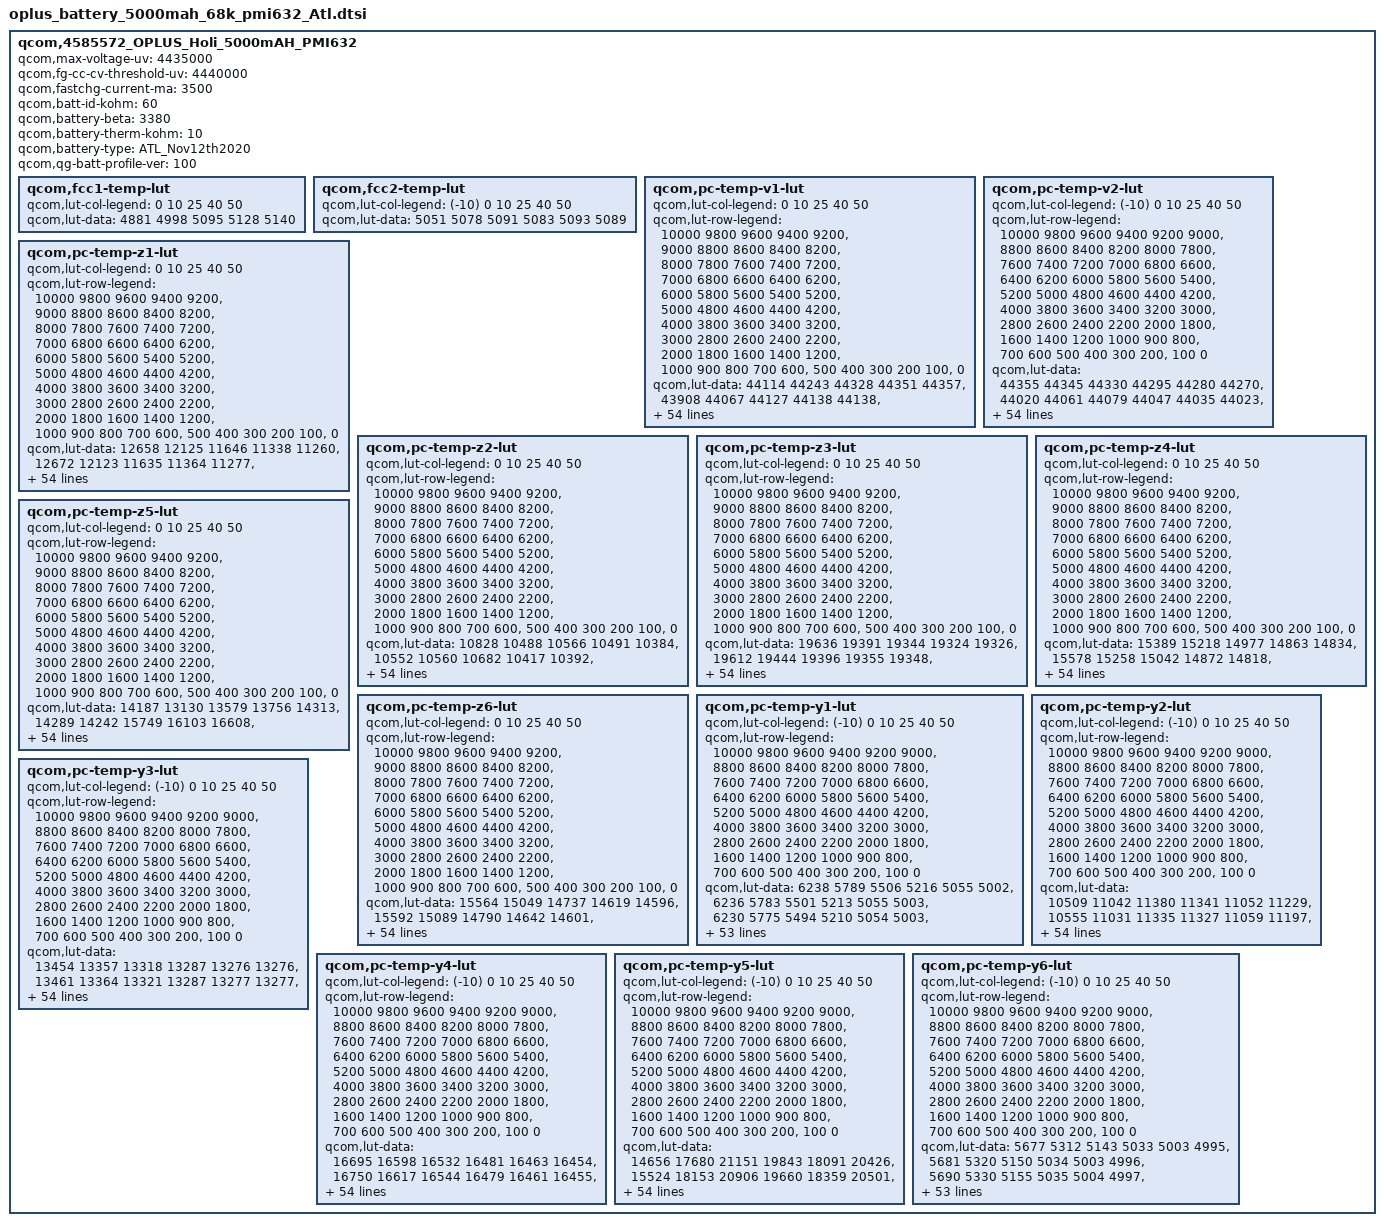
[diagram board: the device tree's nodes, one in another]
qcom,4585572_OPLUS_Holi_5000mAH_PMI632 {
    /* 4585572_OPLUS_Holi_5000mAH_PMI632_averaged_MasterSlave_Nov12th2020 */
    qcom,max-voltage-uv = <4435000>;
    qcom,fg-cc-cv-threshold-uv = <4440000>;
    qcom,fastchg-current-ma = <3500>;
    //qcom,batt-id-kohm = <68>;
    qcom,batt-id-kohm = <60>;
    qcom,battery-beta = <3380>;
    qcom,battery-therm-kohm = <10>;
    qcom,battery-type = "ATL_Nov12th2020";
    qcom,qg-batt-profile-ver = <100>;
    //qcom,jeita-soft-thresholds_oplus = <0x5E68 0x72A>;
    //qcom,jeita-hard-thresholds_oplus = <0x5E68 0x72A>;

	qcom,fcc1-temp-lut {
		qcom,lut-col-legend = <0 10 25 40 50>;
		qcom,lut-data = <4881 4998 5095 5128 5140>;
	};

	qcom,fcc2-temp-lut {
		qcom,lut-col-legend = <(-10) 0 10 25 40 50>;
		qcom,lut-data = <5051 5078 5091 5083 5093 5089>;
	};

	qcom,pc-temp-v1-lut {
		qcom,lut-col-legend = <0 10 25 40 50>;
		qcom,lut-row-legend = <10000 9800 9600 9400 9200>,
			<9000 8800 8600 8400 8200>,
			<8000 7800 7600 7400 7200>,
			<7000 6800 6600 6400 6200>,
			<6000 5800 5600 5400 5200>,
			<5000 4800 4600 4400 4200>,
			<4000 3800 3600 3400 3200>,
			<3000 2800 2600 2400 2200>,
			<2000 1800 1600 1400 1200>,
			<1000 900 800 700 600>,
			<500 400 300 200 100>,
			<0>;
		qcom,lut-data = <44114 44243 44328 44351 44357>,
			<43908 44067 44127 44138 44138>,
			<43693 43854 43932 43944 43944>,
			<43470 43639 43734 43747 43748>,
			<43242 43420 43523 43542 43544>,
			<43005 43193 43302 43328 43330>,
			<42764 42956 43072 43103 43107>,
			<42525 42712 42832 42868 42875>,
			<42287 42470 42588 42623 42635>,
			<42053 42228 42343 42380 42394>,
			<41824 41989 42099 42140 42151>,
			<41600 41756 41859 41901 41911>,
			<41381 41527 41624 41663 41677>,
			<41170 41306 41394 41428 41446>,
			<40962 41091 41169 41202 41221>,
			<40759 40881 40949 40982 40997>,
			<40560 40674 40739 40771 40781>,
			<40367 40472 40536 40567 40574>,
			<40180 40289 40342 40372 40376>,
			<39999 40130 40164 40187 40191>,
			<39827 39949 39991 40014 40021>,
			<39664 39682 39769 39809 39826>,
			<39480 39383 39461 39527 39552>,
			<39231 39172 39202 39262 39286>,
			<38990 39014 39053 39097 39119>,
			<38852 38890 38939 38972 38995>,
			<38760 38799 38830 38854 38875>,
			<38688 38723 38729 38744 38753>,
			<38628 38646 38636 38642 38640>,
			<38577 38569 38546 38541 38537>,
			<38524 38497 38463 38446 38442>,
			<38471 38426 38385 38361 38357>,
			<38419 38359 38311 38283 38282>,
			<38369 38300 38244 38212 38209>,
			<38321 38247 38188 38147 38137>,
			<38275 38199 38135 38086 38065>,
			<38236 38156 38083 38024 37994>,
			<38192 38114 38033 37964 37924>,
			<38121 38049 37968 37891 37842>,
			<38021 37948 37875 37793 37737>,
			<37909 37832 37765 37678 37617>,
			<37781 37708 37645 37558 37492>,
			<37633 37567 37507 37426 37357>,
			<37453 37394 37342 37263 37192>,
			<37292 37236 37189 37122 37052>,
			<37214 37138 37086 37034 36975>,
			<37173 37107 37063 37006 36950>,
			<37154 37088 37042 36990 36931>,
			<37122 37062 37023 36968 36907>,
			<37067 37017 36968 36901 36829>,
			<36846 36784 36716 36619 36528>,
			<36387 36333 36270 36168 36074>,
			<35786 35735 35676 35578 35483>,
			<34956 34909 34860 34764 34666>,
			<33578 33568 33574 33487 33385>,
			<30000 30000 30000 30000 30000>;
	};

	qcom,pc-temp-v2-lut {
		qcom,lut-col-legend = <(-10) 0 10 25 40 50>;
		qcom,lut-row-legend = <10000 9800 9600 9400 9200 9000>,
			<8800 8600 8400 8200 8000 7800>,
			<7600 7400 7200 7000 6800 6600>,
			<6400 6200 6000 5800 5600 5400>,
			<5200 5000 4800 4600 4400 4200>,
			<4000 3800 3600 3400 3200 3000>,
			<2800 2600 2400 2200 2000 1800>,
			<1600 1400 1200 1000 900 800>,
			<700 600 500 400 300 200>,
			<100 0>;
		qcom,lut-data = <44355 44345 44330 44295 44280 44270>,
			<44020 44061 44079 44047 44035 44023>,
			<43716 43798 43840 43810 43801 43787>,
			<43447 43559 43616 43586 43578 43565>,
			<43210 43344 43407 43376 43368 43356>,
			<42977 43125 43191 43159 43152 43142>,
			<42736 42888 42956 42925 42921 42911>,
			<42496 42645 42715 42685 42683 42674>,
			<42257 42398 42473 42443 42443 42435>,
			<42019 42146 42229 42198 42200 42193>,
			<41774 41901 41987 41956 41959 41953>,
			<41500 41663 41747 41717 41721 41715>,
			<41238 41434 41510 41482 41487 41481>,
			<41051 41217 41278 41252 41256 41252>,
			<40913 41010 41052 41029 41031 41027>,
			<40726 40809 40835 40811 40813 40809>,
			<40370 40625 40630 40599 40604 40599>,
			<39981 40428 40429 40393 40401 40396>,
			<39734 40172 40231 40203 40211 40207>,
			<39547 39870 40031 40021 40028 40024>,
			<39353 39600 39803 39814 39824 39822>,
			<39134 39360 39526 39562 39591 39593>,
			<38919 39144 39265 39315 39360 39365>,
			<38724 38955 39058 39104 39143 39152>,
			<38540 38786 38880 38914 38941 38951>,
			<38401 38634 38727 38759 38782 38792>,
			<38301 38499 38595 38631 38655 38665>,
			<38218 38373 38476 38517 38543 38552>,
			<38144 38245 38365 38410 38439 38444>,
			<38078 38126 38261 38311 38343 38345>,
			<38016 38039 38167 38220 38254 38255>,
			<37957 37970 38079 38135 38172 38174>,
			<37899 37916 37998 38057 38094 38095>,
			<37838 37874 37920 37988 38023 38022>,
			<37778 37838 37849 37923 37952 37946>,
			<37714 37796 37795 37850 37863 37847>,
			<37648 37748 37754 37773 37758 37723>,
			<37577 37696 37707 37691 37653 37607>,
			<37497 37643 37646 37603 37552 37507>,
			<37410 37581 37573 37513 37452 37410>,
			<37314 37480 37479 37421 37361 37316>,
			<37207 37324 37361 37326 37271 37219>,
			<37102 37173 37225 37205 37145 37090>,
			<37000 37019 37072 37064 37006 36948>,
			<36900 36873 36919 36931 36887 36835>,
			<36797 36778 36845 36879 36848 36797>,
			<36746 36739 36815 36862 36836 36785>,
			<36696 36702 36786 36845 36821 36769>,
			<36642 36649 36744 36816 36792 36737>,
			<36556 36544 36651 36739 36699 36619>,
			<36389 36305 36390 36478 36381 36279>,
			<36077 35881 35896 35987 35879 35766>,
			<35553 35266 35222 35340 35215 35092>,
			<34736 34352 34290 34447 34284 34145>,
			<33484 32861 32757 33034 32828 32693>,
			<30881 27667 27598 27480 27660 27642>;
	};

	qcom,pc-temp-z1-lut {
		qcom,lut-col-legend = <0 10 25 40 50>;
		qcom,lut-row-legend = <10000 9800 9600 9400 9200>,
			<9000 8800 8600 8400 8200>,
			<8000 7800 7600 7400 7200>,
			<7000 6800 6600 6400 6200>,
			<6000 5800 5600 5400 5200>,
			<5000 4800 4600 4400 4200>,
			<4000 3800 3600 3400 3200>,
			<3000 2800 2600 2400 2200>,
			<2000 1800 1600 1400 1200>,
			<1000 900 800 700 600>,
			<500 400 300 200 100>,
			<0>;
		qcom,lut-data = <12658 12125 11646 11338 11260>,
			<12672 12123 11635 11364 11277>,
			<12666 12125 11632 11360 11278>,
			<12651 12124 11629 11357 11274>,
			<12637 12117 11625 11354 11272>,
			<12626 12107 11618 11352 11270>,
			<12616 12095 11611 11349 11270>,
			<12607 12081 11605 11346 11269>,
			<12599 12071 11599 11341 11268>,
			<12590 12063 11592 11339 11268>,
			<12580 12054 11584 11339 11268>,
			<12568 12040 11580 11338 11268>,
			<12553 12027 11579 11337 11268>,
			<12531 12023 11578 11337 11268>,
			<12515 12021 11576 11336 11268>,
			<12512 12021 11574 11335 11269>,
			<12512 12021 11574 11335 11270>,
			<12510 12022 11576 11336 11270>,
			<12495 12019 11578 11337 11271>,
			<12480 12011 11578 11337 11272>,
			<12482 12005 11578 11338 11273>,
			<12492 12008 11578 11338 11274>,
			<12498 12014 11581 11339 11275>,
			<12500 12018 11584 11341 11276>,
			<12501 12022 11588 11343 11278>,
			<12499 12025 11592 11346 11280>,
			<12492 12025 11595 11348 11282>,
			<12487 12024 11597 11351 11285>,
			<12492 12026 11600 11355 11289>,
			<12500 12036 11604 11358 11292>,
			<12501 12042 11609 11362 11295>,
			<12496 12039 11613 11365 11298>,
			<12491 12035 11618 11368 11301>,
			<12496 12035 11623 11372 11303>,
			<12505 12039 11629 11375 11306>,
			<12508 12044 11634 11379 11309>,
			<12508 12047 11637 11382 11312>,
			<12507 12050 11640 11385 11315>,
			<12514 12057 11644 11388 11317>,
			<12528 12072 11651 11391 11319>,
			<12542 12083 11659 11394 11321>,
			<12553 12086 11665 11398 11324>,
			<12561 12087 11672 11401 11326>,
			<12573 12095 11679 11403 11328>,
			<12581 12101 11685 11407 11330>,
			<12580 12102 11687 11410 11332>,
			<12585 12104 11691 11410 11331>,
			<12568 12092 11691 11410 11332>,
			<12552 12101 11689 11411 11333>,
			<12565 12096 11694 11417 11335>,
			<12586 12108 11708 11419 11339>,
			<12610 12143 11711 11426 11343>,
			<12599 12131 11726 11434 11352>,
			<12621 12156 11738 11445 11362>,
			<12621 12156 11738 11445 11362>,
			<12621 12156 11738 11445 11362>;
	};

	qcom,pc-temp-z2-lut {
		qcom,lut-col-legend = <0 10 25 40 50>;
		qcom,lut-row-legend = <10000 9800 9600 9400 9200>,
			<9000 8800 8600 8400 8200>,
			<8000 7800 7600 7400 7200>,
			<7000 6800 6600 6400 6200>,
			<6000 5800 5600 5400 5200>,
			<5000 4800 4600 4400 4200>,
			<4000 3800 3600 3400 3200>,
			<3000 2800 2600 2400 2200>,
			<2000 1800 1600 1400 1200>,
			<1000 900 800 700 600>,
			<500 400 300 200 100>,
			<0>;
		qcom,lut-data = <10828 10488 10566 10491 10384>,
			<10552 10560 10682 10417 10392>,
			<10471 10619 10695 10528 10387>,
			<10441 10617 10691 10572 10499>,
			<10415 10581 10669 10572 10544>,
			<10383 10541 10612 10527 10505>,
			<10352 10508 10560 10477 10451>,
			<10328 10479 10522 10445 10421>,
			<10308 10455 10490 10414 10399>,
			<10297 10433 10465 10391 10382>,
			<10294 10422 10442 10372 10369>,
			<10293 10421 10436 10361 10350>,
			<10294 10421 10455 10362 10292>,
			<10304 10430 10482 10368 10210>,
			<10319 10468 10503 10362 10199>,
			<10334 10504 10523 10332 10249>,
			<10353 10520 10537 10317 10288>,
			<10376 10532 10552 10309 10296>,
			<10414 10566 10564 10303 10304>,
			<10449 10711 10569 10315 10316>,
			<10469 10823 10578 10341 10330>,
			<10483 10775 10603 10388 10346>,
			<10488 10665 10700 10539 10416>,
			<10484 10616 10768 10670 10492>,
			<10478 10581 10694 10610 10496>,
			<10478 10563 10574 10455 10475>,
			<10483 10573 10564 10413 10495>,
			<10490 10594 10624 10450 10709>,
			<10500 10612 10671 10502 10891>,
			<10513 10632 10689 10563 10799>,
			<10524 10642 10701 10624 10575>,
			<10534 10639 10698 10624 10414>,
			<10544 10634 10684 10556 10283>,
			<10552 10634 10669 10481 10223>,
			<10561 10640 10652 10407 10240>,
			<10565 10647 10638 10347 10276>,
			<10569 10653 10654 10358 10320>,
			<10573 10661 10709 10434 10382>,
			<10579 10673 10754 10508 10444>,
			<10591 10695 10790 10589 10517>,
			<10599 10710 10817 10656 10570>,
			<10602 10712 10829 10671 10557>,
			<10609 10714 10836 10675 10522>,
			<10649 10735 10828 10709 10577>,
			<10919 10858 10846 10690 10601>,
			<10641 10972 10873 10582 10478>,
			<10899 10964 10837 10573 10494>,
			<10447 10978 10820 10572 10497>,
			<10283 11036 10787 10581 10542>,
			<10251 11165 10887 10683 10593>,
			<10198 11230 10959 10535 10420>,
			<10069 11366 10896 10358 10239>,
			<9983 11225 10817 10279 10165>,
			<9826 11072 10729 10213 10102>,
			<9826 11072 10729 10213 10102>,
			<9826 11072 10729 10213 10102>;
	};

	qcom,pc-temp-z3-lut {
		qcom,lut-col-legend = <0 10 25 40 50>;
		qcom,lut-row-legend = <10000 9800 9600 9400 9200>,
			<9000 8800 8600 8400 8200>,
			<8000 7800 7600 7400 7200>,
			<7000 6800 6600 6400 6200>,
			<6000 5800 5600 5400 5200>,
			<5000 4800 4600 4400 4200>,
			<4000 3800 3600 3400 3200>,
			<3000 2800 2600 2400 2200>,
			<2000 1800 1600 1400 1200>,
			<1000 900 800 700 600>,
			<500 400 300 200 100>,
			<0>;
		qcom,lut-data = <19636 19391 19344 19324 19326>,
			<19612 19444 19396 19355 19348>,
			<19636 19516 19420 19379 19366>,
			<19682 19549 19435 19393 19382>,
			<19716 19562 19444 19401 19392>,
			<19736 19570 19453 19405 19397>,
			<19749 19576 19457 19409 19401>,
			<19751 19580 19458 19414 19403>,
			<19750 19581 19458 19419 19405>,
			<19748 19578 19458 19419 19405>,
			<19746 19573 19456 19411 19402>,
			<19743 19568 19452 19402 19397>,
			<19739 19562 19442 19399 19391>,
			<19729 19553 19431 19396 19383>,
			<19720 19541 19426 19392 19378>,
			<19716 19532 19422 19385 19376>,
			<19714 19528 19419 19379 19374>,
			<19708 19526 19415 19374 19371>,
			<19686 19524 19411 19369 19367>,
			<19665 19521 19407 19365 19361>,
			<19665 19522 19403 19360 19352>,
			<19671 19535 19404 19359 19349>,
			<19678 19552 19420 19366 19352>,
			<19688 19552 19432 19372 19355>,
			<19697 19539 19420 19364 19349>,
			<19696 19525 19399 19346 19331>,
			<19688 19516 19394 19341 19327>,
			<19678 19508 19392 19345 19365>,
			<19668 19508 19392 19353 19397>,
			<19659 19513 19399 19371 19397>,
			<19655 19518 19411 19393 19395>,
			<19653 19523 19419 19396 19392>,
			<19651 19527 19427 19391 19380>,
			<19650 19528 19429 19385 19368>,
			<19648 19524 19424 19377 19360>,
			<19646 19519 19417 19369 19352>,
			<19642 19514 19411 19362 19346>,
			<19637 19509 19406 19357 19341>,
			<19632 19505 19402 19354 19339>,
			<19626 19501 19398 19354 19338>,
			<19618 19497 19396 19353 19338>,
			<19608 19492 19394 19355 19341>,
			<19595 19485 19393 19359 19348>,
			<19576 19475 19388 19362 19356>,
			<19521 19449 19378 19357 19357>,
			<19369 19421 19370 19341 19341>,
			<19386 19420 19363 19340 19330>,
			<19281 19403 19363 19333 19325>,
			<19263 19394 19351 19327 19321>,
			<19263 19339 19337 19325 19321>,
			<19263 19348 19338 19355 19350>,
			<19264 19314 19339 19363 19355>,
			<19265 19312 19344 19357 19350>,
			<19269 19310 19340 19359 19350>,
			<19269 19310 19340 19359 19350>,
			<19269 19310 19340 19359 19350>;
	};

	qcom,pc-temp-z4-lut {
		qcom,lut-col-legend = <0 10 25 40 50>;
		qcom,lut-row-legend = <10000 9800 9600 9400 9200>,
			<9000 8800 8600 8400 8200>,
			<8000 7800 7600 7400 7200>,
			<7000 6800 6600 6400 6200>,
			<6000 5800 5600 5400 5200>,
			<5000 4800 4600 4400 4200>,
			<4000 3800 3600 3400 3200>,
			<3000 2800 2600 2400 2200>,
			<2000 1800 1600 1400 1200>,
			<1000 900 800 700 600>,
			<500 400 300 200 100>,
			<0>;
		qcom,lut-data = <15389 15218 14977 14863 14834>,
			<15578 15258 15042 14872 14818>,
			<15572 15229 15019 14890 14851>,
			<15459 15187 14973 14866 14831>,
			<15342 15114 14934 14842 14810>,
			<15247 15041 14897 14819 14792>,
			<15160 14984 14864 14796 14774>,
			<15094 14934 14836 14774 14756>,
			<15042 14895 14810 14753 14739>,
			<14997 14863 14787 14738 14726>,
			<14955 14837 14766 14727 14713>,
			<14918 14814 14751 14718 14705>,
			<14889 14795 14742 14710 14702>,
			<14866 14779 14734 14703 14700>,
			<14846 14766 14726 14698 14696>,
			<14826 14757 14718 14694 14689>,
			<14806 14753 14711 14690 14683>,
			<14801 14750 14704 14685 14678>,
			<14805 14743 14699 14680 14674>,
			<14808 14722 14696 14676 14671>,
			<14802 14707 14693 14673 14670>,
			<14783 14739 14701 14674 14670>,
			<14775 14802 14762 14729 14722>,
			<14826 14840 14815 14789 14784>,
			<14889 14867 14832 14808 14800>,
			<14897 14879 14843 14819 14808>,
			<14896 14873 14843 14820 14805>,
			<14894 14859 14832 14803 14755>,
			<14884 14843 14817 14779 14704>,
			<14867 14823 14795 14746 14690>,
			<14853 14804 14768 14709 14682>,
			<14840 14788 14747 14693 14677>,
			<14828 14774 14728 14685 14674>,
			<14818 14766 14718 14682 14673>,
			<14808 14762 14714 14683 14673>,
			<14800 14758 14712 14684 14673>,
			<14791 14752 14712 14684 14673>,
			<14784 14747 14713 14685 14674>,
			<14778 14746 14715 14686 14676>,
			<14774 14746 14722 14698 14689>,
			<14767 14746 14728 14709 14702>,
			<14753 14737 14722 14704 14698>,
			<14739 14721 14710 14694 14687>,
			<14727 14712 14707 14693 14685>,
			<14703 14692 14696 14689 14678>,
			<14814 14675 14672 14675 14664>,
			<14792 14668 14667 14668 14664>,
			<14900 14675 14651 14657 14653>,
			<14912 14674 14648 14641 14635>,
			<14908 14735 14659 14637 14629>,
			<14909 14736 14686 14642 14642>,
			<14919 14784 14693 14646 14650>,
			<14923 14786 14689 14654 14658>,
			<14928 14794 14696 14656 14660>,
			<14928 14794 14696 14656 14660>,
			<14928 14794 14696 14656 14660>;
	};

	qcom,pc-temp-z5-lut {
		qcom,lut-col-legend = <0 10 25 40 50>;
		qcom,lut-row-legend = <10000 9800 9600 9400 9200>,
			<9000 8800 8600 8400 8200>,
			<8000 7800 7600 7400 7200>,
			<7000 6800 6600 6400 6200>,
			<6000 5800 5600 5400 5200>,
			<5000 4800 4600 4400 4200>,
			<4000 3800 3600 3400 3200>,
			<3000 2800 2600 2400 2200>,
			<2000 1800 1600 1400 1200>,
			<1000 900 800 700 600>,
			<500 400 300 200 100>,
			<0>;
		qcom,lut-data = <14187 13130 13579 13756 14313>,
			<14289 14242 15749 16103 16608>,
			<14756 16017 16673 17585 17906>,
			<15527 16999 17273 18633 19559>,
			<16332 17475 17667 19219 20852>,
			<17075 17941 18022 19505 21646>,
			<17816 18579 18371 19804 22349>,
			<18494 19314 18732 20797 23214>,
			<19090 20013 19136 22267 24208>,
			<19768 20670 19719 22603 25182>,
			<20714 21338 20477 22378 26352>,
			<21823 22103 20807 22216 27064>,
			<22842 22925 20833 22774 26469>,
			<23705 23620 20861 23761 25295>,
			<24777 24164 21205 24157 25233>,
			<27141 24869 22095 24156 26766>,
			<30433 26445 22979 24122 28556>,
			<31449 28297 23890 24337 30328>,
			<29982 29026 24767 24738 31804>,
			<28469 28918 25392 25278 31700>,
			<29642 29396 26049 26210 30414>,
			<34452 39959 28344 27419 29427>,
			<39882 55433 37471 29656 29081>,
			<46969 56432 43724 31380 28683>,
			<52972 44685 37078 28083 25577>,
			<52527 34317 25545 20143 18507>,
			<47022 29801 21617 17464 16384>,
			<41935 26826 20109 17182 20507>,
			<38641 26468 19586 17073 25337>,
			<36194 27249 20321 19373 28215>,
			<35802 28499 21949 24048 30445>,
			<36107 31291 24560 26842 30613>,
			<36619 35176 29126 28896 28878>,
			<37975 37838 32389 29820 27561>,
			<40099 40004 34176 29697 27361>,
			<41198 41086 35313 29449 27270>,
			<41724 41111 35619 29329 27138>,
			<42088 40915 35531 28998 26949>,
			<42410 40634 35023 28565 26603>,
			<42802 39962 32538 27202 25016>,
			<42806 39032 29913 25802 23421>,
			<40315 37496 28989 25461 23651>,
			<37955 35493 28230 25322 24754>,
			<36798 33137 25948 25886 28062>,
			<34303 32627 25473 25096 29752>,
			<18307 29434 26993 21261 23220>,
			<17153 29307 24674 21501 19363>,
			<12097 22933 27321 20929 19954>,
			<11791 21580 23866 23163 23629>,
			<11809 14713 19736 23275 25892>,
			<11891 15419 17022 28454 29405>,
			<11824 13158 15633 26781 25998>,
			<11742 12994 15747 21307 20694>,
			<11839 12797 15085 19615 18612>,
			<11839 12797 15085 19615 18612>,
			<11839 12797 15085 19615 18612>;
	};

	qcom,pc-temp-z6-lut {
		qcom,lut-col-legend = <0 10 25 40 50>;
		qcom,lut-row-legend = <10000 9800 9600 9400 9200>,
			<9000 8800 8600 8400 8200>,
			<8000 7800 7600 7400 7200>,
			<7000 6800 6600 6400 6200>,
			<6000 5800 5600 5400 5200>,
			<5000 4800 4600 4400 4200>,
			<4000 3800 3600 3400 3200>,
			<3000 2800 2600 2400 2200>,
			<2000 1800 1600 1400 1200>,
			<1000 900 800 700 600>,
			<500 400 300 200 100>,
			<0>;
		qcom,lut-data = <15564 15049 14737 14619 14596>,
			<15592 15089 14790 14642 14601>,
			<15584 15096 14786 14657 14622>,
			<15531 15091 14776 14656 14622>,
			<15474 15056 14765 14653 14622>,
			<15423 15017 14751 14646 14618>,
			<15373 14987 14738 14637 14611>,
			<15331 14960 14725 14630 14606>,
			<15295 14936 14712 14624 14600>,
			<15262 14915 14701 14617 14594>,
			<15232 14896 14690 14608 14588>,
			<15205 14879 14680 14599 14581>,
			<15181 14863 14670 14593 14575>,
			<15160 14849 14661 14589 14570>,
			<15141 14836 14653 14583 14565>,
			<15123 14826 14648 14577 14561>,
			<15108 14821 14642 14572 14557>,
			<15094 14817 14637 14567 14553>,
			<15082 14811 14633 14562 14549>,
			<15072 14802 14629 14558 14544>,
			<15067 14796 14626 14554 14538>,
			<15063 14818 14630 14554 14537>,
			<15063 14854 14668 14583 14562>,
			<15091 14868 14695 14612 14591>,
			<15125 14873 14694 14613 14592>,
			<15129 14875 14691 14610 14588>,
			<15126 14870 14688 14608 14585>,
			<15121 14860 14683 14604 14582>,
			<15112 14854 14679 14599 14580>,
			<15100 14850 14674 14595 14576>,
			<15093 14846 14669 14591 14572>,
			<15088 14842 14665 14587 14567>,
			<15084 14838 14662 14582 14561>,
			<15081 14836 14659 14578 14555>,
			<15078 14834 14655 14574 14550>,
			<15075 14832 14652 14570 14547>,
			<15071 14829 14650 14567 14544>,
			<15069 14825 14648 14564 14541>,
			<15069 14825 14648 14563 14540>,
			<15070 14827 14650 14568 14545>,
			<15071 14828 14653 14572 14550>,
			<15068 14825 14651 14572 14550>,
			<15064 14821 14647 14570 14550>,
			<15059 14817 14644 14571 14552>,
			<15033 14803 14636 14567 14551>,
			<15011 14786 14624 14554 14536>,
			<15010 14782 14618 14550 14532>,
			<15004 14777 14612 14542 14524>,
			<15001 14773 14604 14532 14513>,
			<15004 14775 14604 14529 14510>,
			<15016 14786 14618 14548 14533>,
			<15028 14794 14624 14557 14542>,
			<15040 14801 14629 14559 14545>,
			<15059 14812 14633 14564 14549>,
			<15059 14812 14633 14564 14549>,
			<15059 14812 14633 14564 14549>;
	};

	qcom,pc-temp-y1-lut {
		qcom,lut-col-legend = <(-10) 0 10 25 40 50>;
		qcom,lut-row-legend = <10000 9800 9600 9400 9200 9000>,
			<8800 8600 8400 8200 8000 7800>,
			<7600 7400 7200 7000 6800 6600>,
			<6400 6200 6000 5800 5600 5400>,
			<5200 5000 4800 4600 4400 4200>,
			<4000 3800 3600 3400 3200 3000>,
			<2800 2600 2400 2200 2000 1800>,
			<1600 1400 1200 1000 900 800>,
			<700 600 500 400 300 200>,
			<100 0>;
		qcom,lut-data = <6238 5789 5506 5216 5055 5002>,
			<6236 5783 5501 5213 5055 5003>,
			<6230 5775 5494 5210 5054 5003>,
			<6223 5768 5487 5206 5053 5003>,
			<6218 5762 5481 5203 5051 5003>,
			<6216 5758 5478 5200 5050 5002>,
			<6208 5757 5476 5196 5047 5001>,
			<6197 5755 5475 5194 5044 4999>,
			<6193 5752 5475 5192 5043 4999>,
			<6187 5744 5473 5191 5042 4999>,
			<6184 5740 5473 5190 5042 4999>,
			<6192 5744 5472 5188 5041 4998>,
			<6203 5750 5471 5186 5040 4997>,
			<6205 5750 5467 5184 5039 4997>,
			<6208 5748 5461 5183 5040 4997>,
			<6210 5747 5458 5182 5040 4997>,
			<6201 5748 5456 5182 5040 4997>,
			<6191 5749 5455 5182 5041 4997>,
			<6194 5752 5455 5183 5040 4998>,
			<6205 5756 5454 5185 5040 4999>,
			<6213 5758 5454 5187 5040 5000>,
			<6220 5764 5455 5189 5041 5000>,
			<6225 5769 5456 5190 5043 5000>,
			<6217 5768 5458 5192 5044 5001>,
			<6201 5764 5460 5195 5045 5002>,
			<6194 5762 5460 5197 5047 5003>,
			<6197 5757 5460 5199 5048 5005>,
			<6200 5753 5460 5201 5049 5007>,
			<6200 5755 5467 5203 5051 5008>,
			<6199 5759 5475 5207 5053 5010>,
			<6199 5760 5478 5210 5055 5011>,
			<6203 5759 5480 5213 5058 5013>,
			<6207 5759 5480 5216 5060 5014>,
			<6209 5765 5480 5219 5064 5017>,
			<6212 5775 5480 5223 5067 5019>,
			<6210 5774 5480 5225 5068 5021>,
			<6194 5767 5481 5227 5068 5022>,
			<6182 5763 5482 5228 5068 5023>,
			<6193 5770 5487 5232 5070 5024>,
			<6213 5777 5493 5235 5072 5025>,
			<6216 5777 5495 5236 5074 5026>,
			<6204 5777 5496 5238 5075 5028>,
			<6200 5773 5503 5240 5076 5028>,
			<6196 5771 5513 5245 5078 5029>,
			<6229 5782 5512 5251 5079 5032>,
			<6236 5790 5514 5254 5081 5034>,
			<6232 5783 5515 5255 5082 5034>,
			<6235 5796 5513 5255 5082 5035>,
			<6273 5789 5515 5256 5083 5035>,
			<6266 5788 5516 5258 5082 5036>,
			<6285 5793 5520 5258 5084 5038>,
			<6362 5817 5535 5261 5088 5040>,
			<6429 5893 5545 5271 5094 5045>,
			<6505 5946 5568 5289 5100 5052>,
			<6505 5946 5568 5289 5100 5052>,
			<6505 5946 5568 5289 5100 5052>;
	};

	qcom,pc-temp-y2-lut {
		qcom,lut-col-legend = <(-10) 0 10 25 40 50>;
		qcom,lut-row-legend = <10000 9800 9600 9400 9200 9000>,
			<8800 8600 8400 8200 8000 7800>,
			<7600 7400 7200 7000 6800 6600>,
			<6400 6200 6000 5800 5600 5400>,
			<5200 5000 4800 4600 4400 4200>,
			<4000 3800 3600 3400 3200 3000>,
			<2800 2600 2400 2200 2000 1800>,
			<1600 1400 1200 1000 900 800>,
			<700 600 500 400 300 200>,
			<100 0>;
		qcom,lut-data = <10509 11042 11380 11341 11052 11229>,
			<10555 11031 11335 11327 11059 11197>,
			<10608 11020 11292 11307 11056 11135>,
			<10661 11009 11250 11284 11044 11062>,
			<10705 10999 11212 11259 11025 10997>,
			<10732 10990 11175 11235 11002 10959>,
			<10747 10980 11135 11192 10962 10931>,
			<10757 10972 11103 11147 10922 10905>,
			<10754 10971 11093 11134 10915 10881>,
			<10739 10974 11088 11129 10937 10828>,
			<10732 10977 11086 11128 10942 10801>,
			<10811 10984 11095 11132 10932 10800>,
			<10910 10997 11111 11140 10925 10805>,
			<10914 11029 11132 11152 10920 10814>,
			<10885 11088 11165 11168 10908 10822>,
			<10872 11116 11203 11193 10912 10830>,
			<10904 11121 11253 11242 10963 10837>,
			<10948 11125 11305 11303 11031 10847>,
			<10976 11149 11358 11367 11085 10868>,
			<11000 11196 11406 11435 11140 10911>,
			<10992 11211 11414 11452 11209 10980>,
			<10706 11207 11382 11435 11313 11151>,
			<10405 11203 11357 11419 11377 11272>,
			<10252 11217 11367 11416 11324 11239>,
			<9915 11248 11390 11416 11228 11174>,
			<9758 11262 11409 11422 11209 11160>,
			<9733 11268 11428 11458 11228 11176>,
			<9715 11270 11447 11500 11253 11198>,
			<9704 11268 11472 11544 11285 11227>,
			<9696 11263 11496 11593 11326 11262>,
			<9691 11259 11503 11618 11364 11300>,
			<9686 11255 11504 11633 11406 11376>,
			<9683 11248 11502 11643 11459 11433>,
			<9680 11213 11494 11669 11558 11491>,
			<9678 11148 11481 11696 11648 11548>,
			<9676 11017 11466 11684 11628 11527>,
			<9673 10642 11447 11630 11520 11427>,
			<9671 10412 11421 11588 11443 11370>,
			<9670 10562 11383 11563 11399 11362>,
			<9669 10763 11333 11544 11367 11355>,
			<9668 10511 11266 11531 11354 11321>,
			<9667 9832 11176 11520 11347 11260>,
			<9665 9717 11084 11504 11327 11216>,
			<9664 9698 10973 11476 11294 11174>,
			<9663 9686 10897 11410 11247 11070>,
			<9662 9678 10784 11292 11047 10928>,
			<9661 9675 10712 11260 11083 10890>,
			<9660 9671 10663 11264 11107 10950>,
			<9658 9668 10611 11243 11067 10957>,
			<9656 9665 10522 11254 11077 10916>,
			<9653 9661 10081 11248 10964 10863>,
			<9650 9657 9789 11157 10875 10824>,
			<9649 9652 9694 11055 10807 10713>,
			<9648 9651 9664 10924 10717 10581>,
			<9648 9651 9664 10924 10717 10581>,
			<9648 9651 9664 10924 10717 10581>;
	};

	qcom,pc-temp-y3-lut {
		qcom,lut-col-legend = <(-10) 0 10 25 40 50>;
		qcom,lut-row-legend = <10000 9800 9600 9400 9200 9000>,
			<8800 8600 8400 8200 8000 7800>,
			<7600 7400 7200 7000 6800 6600>,
			<6400 6200 6000 5800 5600 5400>,
			<5200 5000 4800 4600 4400 4200>,
			<4000 3800 3600 3400 3200 3000>,
			<2800 2600 2400 2200 2000 1800>,
			<1600 1400 1200 1000 900 800>,
			<700 600 500 400 300 200>,
			<100 0>;
		qcom,lut-data = <13454 13357 13318 13287 13276 13276>,
			<13461 13364 13321 13287 13277 13277>,
			<13468 13371 13324 13289 13278 13277>,
			<13476 13377 13327 13290 13279 13278>,
			<13481 13382 13330 13291 13281 13279>,
			<13486 13386 13332 13293 13282 13280>,
			<13489 13389 13333 13294 13282 13280>,
			<13491 13391 13334 13296 13283 13281>,
			<13490 13391 13335 13296 13284 13282>,
			<13487 13390 13338 13297 13285 13282>,
			<13483 13388 13338 13297 13286 13283>,
			<13473 13384 13338 13297 13287 13284>,
			<13462 13380 13338 13298 13287 13285>,
			<13456 13380 13336 13300 13287 13285>,
			<13452 13381 13333 13303 13288 13285>,
			<13447 13381 13331 13304 13288 13285>,
			<13439 13378 13329 13301 13291 13287>,
			<13430 13373 13328 13299 13293 13288>,
			<13425 13369 13329 13298 13293 13288>,
			<13422 13365 13331 13298 13293 13289>,
			<13417 13361 13332 13298 13293 13289>,
			<13404 13356 13326 13297 13291 13287>,
			<13391 13351 13320 13294 13287 13285>,
			<13385 13348 13316 13292 13283 13281>,
			<13378 13346 13314 13289 13279 13278>,
			<13376 13343 13313 13288 13279 13277>,
			<13380 13341 13312 13288 13279 13278>,
			<13386 13338 13312 13288 13279 13279>,
			<13393 13334 13311 13288 13279 13278>,
			<13404 13330 13310 13287 13279 13277>,
			<13416 13328 13309 13287 13279 13277>,
			<13432 13325 13308 13287 13278 13277>,
			<13451 13324 13307 13287 13277 13277>,
			<13473 13328 13307 13288 13279 13278>,
			<13500 13336 13307 13288 13280 13279>,
			<13532 13339 13308 13288 13280 13279>,
			<13572 13339 13310 13288 13279 13278>,
			<13617 13339 13311 13287 13279 13278>,
			<13668 13347 13312 13287 13278 13278>,
			<13724 13359 13313 13286 13278 13279>,
			<13781 13369 13314 13286 13279 13280>,
			<13840 13379 13316 13287 13282 13280>,
			<13909 13397 13318 13287 13281 13280>,
			<13991 13425 13319 13287 13279 13277>,
			<14084 13450 13320 13285 13277 13276>,
			<14154 13489 13325 13289 13283 13282>,
			<14249 13535 13328 13292 13287 13284>,
			<14371 13598 13336 13296 13290 13287>,
			<14537 13677 13346 13302 13292 13288>,
			<14789 13792 13357 13305 13291 13285>,
			<15483 13976 13366 13303 13286 13283>,
			<17427 14347 13392 13302 13286 13284>,
			<22756 15678 13486 13305 13289 13287>,
			<40773 21065 13793 13313 13295 13294>,
			<40773 21065 13793 13313 13295 13294>,
			<40773 21065 13793 13313 13295 13294>;
	};

	qcom,pc-temp-y4-lut {
		qcom,lut-col-legend = <(-10) 0 10 25 40 50>;
		qcom,lut-row-legend = <10000 9800 9600 9400 9200 9000>,
			<8800 8600 8400 8200 8000 7800>,
			<7600 7400 7200 7000 6800 6600>,
			<6400 6200 6000 5800 5600 5400>,
			<5200 5000 4800 4600 4400 4200>,
			<4000 3800 3600 3400 3200 3000>,
			<2800 2600 2400 2200 2000 1800>,
			<1600 1400 1200 1000 900 800>,
			<700 600 500 400 300 200>,
			<100 0>;
		qcom,lut-data = <16695 16598 16532 16481 16463 16454>,
			<16750 16617 16544 16479 16461 16455>,
			<16818 16656 16560 16479 16460 16456>,
			<16888 16700 16576 16480 16459 16457>,
			<16945 16735 16589 16481 16458 16457>,
			<16977 16749 16594 16481 16458 16458>,
			<16989 16749 16592 16482 16459 16457>,
			<16997 16749 16589 16483 16460 16457>,
			<17008 16749 16588 16484 16461 16457>,
			<17022 16750 16587 16489 16463 16459>,
			<17030 16753 16587 16494 16465 16461>,
			<17029 16768 16593 16500 16469 16463>,
			<17029 16793 16604 16506 16473 16465>,
			<17057 16818 16618 16511 16479 16468>,
			<17152 16846 16638 16516 16485 16473>,
			<17193 16875 16663 16524 16490 16478>,
			<17044 16914 16704 16541 16495 16482>,
			<16864 16940 16733 16563 16501 16488>,
			<16830 16902 16734 16590 16514 16498>,
			<16819 16794 16730 16619 16534 16510>,
			<16807 16719 16717 16624 16538 16514>,
			<16782 16675 16647 16587 16532 16511>,
			<16757 16643 16579 16542 16522 16506>,
			<16737 16619 16549 16510 16498 16489>,
			<16712 16600 16528 16482 16468 16464>,
			<16704 16586 16522 16477 16462 16459>,
			<16707 16577 16520 16478 16464 16458>,
			<16711 16567 16519 16480 16466 16459>,
			<16715 16548 16520 16485 16471 16462>,
			<16720 16529 16523 16493 16479 16471>,
			<16724 16526 16524 16500 16488 16479>,
			<16732 16536 16526 16507 16499 16488>,
			<16740 16548 16526 16513 16508 16496>,
			<16745 16558 16521 16522 16514 16504>,
			<16752 16570 16513 16528 16517 16509>,
			<16758 16592 16516 16527 16514 16505>,
			<16762 16633 16528 16516 16498 16486>,
			<16764 16660 16540 16503 16485 16475>,
			<16763 16663 16550 16490 16475 16472>,
			<16760 16664 16558 16479 16469 16470>,
			<16756 16669 16560 16481 16470 16473>,
			<16753 16678 16561 16487 16474 16479>,
			<16752 16673 16565 16487 16471 16474>,
			<16757 16655 16566 16484 16460 16458>,
			<16764 16637 16541 16470 16446 16440>,
			<16751 16640 16549 16476 16455 16457>,
			<16764 16655 16565 16487 16471 16484>,
			<16779 16674 16584 16503 16500 16518>,
			<16800 16708 16613 16529 16536 16552>,
			<16822 16743 16649 16550 16541 16540>,
			<16910 16766 16671 16517 16476 16475>,
			<17244 16789 16680 16497 16466 16465>,
			<18469 17033 16720 16510 16467 16465>,
			<26826 19738 16816 16540 16474 16471>,
			<26826 19738 16816 16540 16474 16471>,
			<26826 19738 16816 16540 16474 16471>;
	};

	qcom,pc-temp-y5-lut {
		qcom,lut-col-legend = <(-10) 0 10 25 40 50>;
		qcom,lut-row-legend = <10000 9800 9600 9400 9200 9000>,
			<8800 8600 8400 8200 8000 7800>,
			<7600 7400 7200 7000 6800 6600>,
			<6400 6200 6000 5800 5600 5400>,
			<5200 5000 4800 4600 4400 4200>,
			<4000 3800 3600 3400 3200 3000>,
			<2800 2600 2400 2200 2000 1800>,
			<1600 1400 1200 1000 900 800>,
			<700 600 500 400 300 200>,
			<100 0>;
		qcom,lut-data = <14656 17680 21151 19843 18091 20426>,
			<15524 18153 20906 19660 18359 20501>,
			<16403 18755 20633 19263 18476 20467>,
			<17235 19349 20346 18794 18474 20363>,
			<17960 19795 20060 18387 18388 20231>,
			<18522 19953 19789 18179 18247 20109>,
			<19025 19903 19390 17975 17990 19869>,
			<19391 19787 18937 17679 17675 19534>,
			<19416 19493 18654 17316 17440 19098>,
			<19299 18743 18459 16662 17248 18303>,
			<19093 18033 18164 16074 17001 17800>,
			<18139 17368 17496 15542 16596 17541>,
			<17069 16901 16697 15179 16127 17280>,
			<17724 16886 16003 15240 15643 16870>,
			<20484 16977 15345 15495 15144 16205>,
			<21782 17245 15160 15545 15007 15793>,
			<20999 19479 15381 14682 15247 15674>,
			<20092 21905 15837 13837 15473 15669>,
			<20473 22621 17882 13966 15357 15526>,
			<21923 23034 21730 14571 15082 15226>,
			<22520 23120 23303 15681 15297 15484>,
			<20840 23024 23766 19120 17870 17595>,
			<18946 22937 23962 21756 19891 19313>,
			<17610 23002 23496 21629 19681 19462>,
			<14716 23178 22646 21256 19186 19527>,
			<13301 23348 22513 21047 18750 19494>,
			<13002 23544 22873 20601 18034 19197>,
			<12838 23656 23123 20236 17464 18733>,
			<12827 22636 22909 19959 17240 17630>,
			<12897 20502 22565 19632 17069 16313>,
			<12918 18855 22581 19577 16779 16019>,
			<12987 17241 22976 19538 16323 15960>,
			<13091 16449 23234 19642 16129 15949>,
			<13205 17340 23026 20187 17227 16817>,
			<13395 18853 22689 20960 18770 18166>,
			<13593 19276 22521 21645 19384 18805>,
			<13892 18284 22160 22438 19760 19185>,
			<14164 17708 21841 22774 19856 19726>,
			<14330 19398 21068 21867 19369 21103>,
			<14457 21584 20129 20464 18859 22330>,
			<14380 20248 19580 19550 19729 22299>,
			<13797 15512 19065 18896 21581 22051>,
			<13493 14801 18503 19007 21216 22130>,
			<13308 14711 18247 19253 19972 21470>,
			<13216 14207 18916 18388 17721 18658>,
			<13168 14001 18754 18311 18207 18733>,
			<13178 13945 17745 17724 19184 18009>,
			<13419 14110 17647 18394 18822 16903>,
			<13712 14016 17407 19029 17829 16425>,
			<13761 14092 17181 19381 17100 15546>,
			<12938 14368 16106 20925 17954 17346>,
			<11367 14317 14637 21287 17845 17185>,
			<9893 12585 14319 21452 18106 17691>,
			<9056 9761 13767 21980 21725 23348>,
			<9056 9761 13767 21980 21725 23348>,
			<9056 9761 13767 21980 21725 23348>;
	};

	qcom,pc-temp-y6-lut {
		qcom,lut-col-legend = <(-10) 0 10 25 40 50>;
		qcom,lut-row-legend = <10000 9800 9600 9400 9200 9000>,
			<8800 8600 8400 8200 8000 7800>,
			<7600 7400 7200 7000 6800 6600>,
			<6400 6200 6000 5800 5600 5400>,
			<5200 5000 4800 4600 4400 4200>,
			<4000 3800 3600 3400 3200 3000>,
			<2800 2600 2400 2200 2000 1800>,
			<1600 1400 1200 1000 900 800>,
			<700 600 500 400 300 200>,
			<100 0>;
		qcom,lut-data = <5677 5312 5143 5033 5003 4995>,
			<5681 5320 5150 5034 5003 4996>,
			<5690 5330 5155 5035 5004 4997>,
			<5699 5338 5158 5036 5004 4998>,
			<5707 5344 5159 5036 5005 4999>,
			<5710 5346 5160 5037 5005 4999>,
			<5710 5344 5158 5038 5006 5000>,
			<5709 5342 5155 5039 5007 5000>,
			<5708 5338 5154 5040 5008 5001>,
			<5706 5333 5152 5041 5009 5002>,
			<5702 5331 5152 5042 5010 5003>,
			<5692 5332 5152 5044 5012 5004>,
			<5682 5333 5153 5046 5014 5005>,
			<5688 5337 5154 5048 5015 5007>,
			<5714 5344 5157 5051 5017 5008>,
			<5724 5351 5161 5055 5019 5010>,
			<5680 5359 5170 5058 5022 5012>,
			<5627 5364 5178 5062 5025 5014>,
			<5619 5352 5179 5069 5030 5018>,
			<5618 5320 5179 5078 5035 5022>,
			<5616 5296 5176 5079 5036 5023>,
			<5604 5281 5152 5067 5032 5020>,
			<5590 5270 5128 5053 5026 5016>,
			<5583 5263 5117 5042 5016 5009>,
			<5576 5259 5110 5032 5005 4999>,
			<5575 5256 5109 5030 5003 4997>,
			<5585 5255 5109 5031 5004 4997>,
			<5601 5253 5109 5032 5004 4998>,
			<5617 5251 5109 5033 5006 4999>,
			<5636 5248 5111 5036 5009 5001>,
			<5657 5248 5112 5038 5011 5003>,
			<5680 5256 5114 5041 5014 5006>,
			<5705 5267 5115 5043 5016 5009>,
			<5734 5280 5115 5046 5019 5012>,
			<5768 5297 5116 5049 5022 5014>,
			<5803 5316 5118 5049 5021 5012>,
			<5842 5338 5125 5046 5016 5006>,
			<5883 5362 5132 5043 5011 5004>,
			<5928 5393 5139 5039 5008 5004>,
			<5976 5425 5147 5036 5007 5004>,
			<6025 5450 5154 5037 5008 5005>,
			<6075 5472 5162 5039 5011 5007>,
			<6136 5502 5174 5041 5010 5005>,
			<6212 5541 5187 5041 5005 4999>,
			<6298 5574 5185 5036 5000 4994>,
			<6364 5629 5204 5042 5008 5003>,
			<6449 5684 5221 5048 5016 5013>,
			<6560 5751 5248 5056 5026 5025>,
			<6712 5835 5281 5068 5038 5035>,
			<6954 5954 5322 5076 5038 5030>,
			<7589 6132 5362 5065 5017 5010>,
			<9245 6471 5423 5060 5014 5008>,
			<13523 7649 5567 5069 5017 5011>,
			<28290 12337 5919 5088 5025 5019>,
			<28290 12337 5919 5088 5025 5019>,
			<28290 12337 5919 5088 5025 5019>;
	};

};
